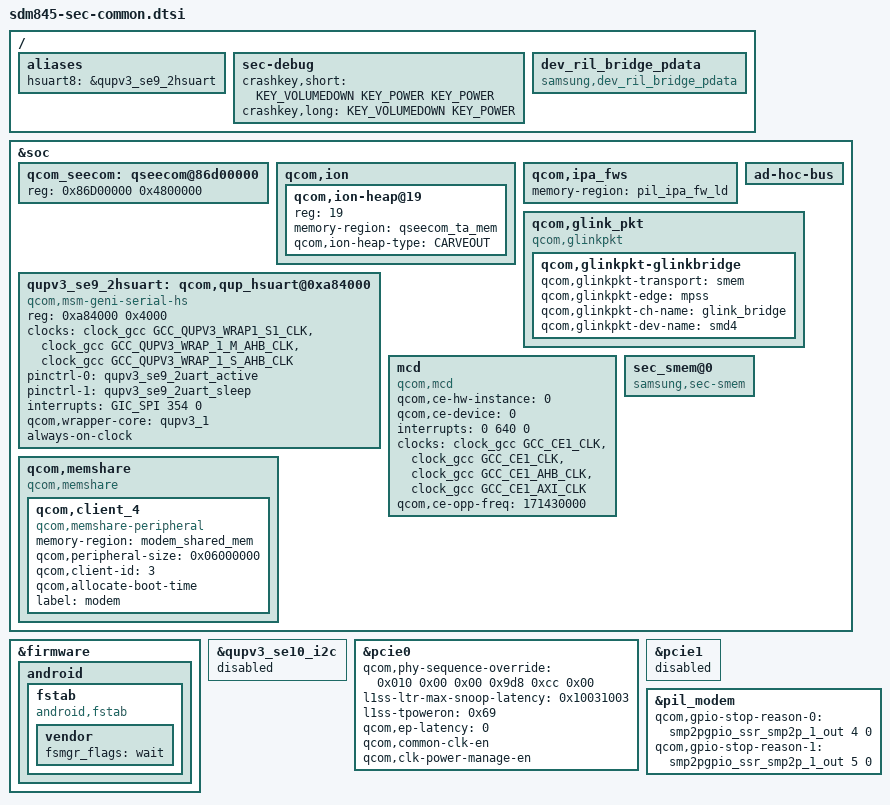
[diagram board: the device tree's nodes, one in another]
/* Copyright (c) 2016-2017, The Linux Foundation. All rights reserved.
 *
 * This program is free software; you can redistribute it and/or modify
 * it under the terms of the GNU General Public License version 2 and
 * only version 2 as published by the Free Software Foundation.
 *
 * This program is distributed in the hope that it will be useful,
 * but WITHOUT ANY WARRANTY; without even the implied warranty of
 * MERCHANTABILITY or FITNESS FOR A PARTICULAR PURPOSE.  See the
 * GNU General Public License for more details.
 */

#include <dt-bindings/input/linux-event-codes.h>
#include "sdm845-sec-memory-common.dtsi"
#include "sdm845-sec-argos-common.dtsi"
#include "input_booster.dtsi"

/{
	aliases {
		hsuart8 = &qupv3_se9_2hsuart;
	};

	sec-debug {
		crashkey,short = <KEY_VOLUMEDOWN KEY_POWER KEY_POWER>;
		crashkey,long = <KEY_VOLUMEDOWN KEY_POWER>;
	};

	dev_ril_bridge_pdata {
		compatible = "samsung,dev_ril_bridge_pdata";
		status = "okay";
	};
};

&soc {
	qcom_seecom: qseecom@86d00000 {
		reg = <0x86D00000 0x4800000>;
	};

	qcom,ion {
		/delete-node/ qcom,ion-heap@19;
		qcom,ion-heap@19 { /* QSEECOM TA HEAP */
			reg = <19>;
			memory-region = <&qseecom_ta_mem>;
			qcom,ion-heap-type = "CARVEOUT";
		};
	};

	qcom,ipa_fws {
		memory-region = <&pil_ipa_fw_ld>;
	};

	ad-hoc-bus {
		/delete-node/ mas-qhm-tic;
		/delete-node/ mas-xm-qdss-dap;
	};
	qupv3_se9_2hsuart: qcom,qup_hsuart@0xa84000 {
		compatible = "qcom,msm-geni-serial-hs", "qcom,msm-geni-uart";
		reg = <0xa84000 0x4000>;
		reg-names = "se_phys";
		clock-names = "se-clk", "m-ahb", "s-ahb";
		clocks = <&clock_gcc GCC_QUPV3_WRAP1_S1_CLK>,
			<&clock_gcc GCC_QUPV3_WRAP_1_M_AHB_CLK>,
			<&clock_gcc GCC_QUPV3_WRAP_1_S_AHB_CLK>;
		pinctrl-names = "default", "sleep";
		pinctrl-0 = <&qupv3_se9_2uart_active>;
		pinctrl-1 = <&qupv3_se9_2uart_sleep>;
		interrupts = <GIC_SPI 354 0>;
		qcom,wrapper-core = <&qupv3_1>;
		status = "ok";
		always-on-clock;
	};

	qcom,glink_pkt {
		compatible = "qcom,glinkpkt";

		qcom,glinkpkt-glinkbridge {
			qcom,glinkpkt-transport = "smem";
			qcom,glinkpkt-edge = "mpss";
			qcom,glinkpkt-ch-name = "glink_bridge";
			qcom,glinkpkt-dev-name = "smd4";
		};
	};

	mcd {
		compatible = "qcom,mcd";
		qcom,ce-hw-instance = <0>;
		qcom,ce-device = <0>;
		interrupts = <0 640 0>;
		interrupt-names = "mcd_irq";
		clock-names = "core_clk_src", "core_clk",
				"iface_clk", "bus_clk";
		clocks = <&clock_gcc GCC_CE1_CLK>,
				<&clock_gcc GCC_CE1_CLK>,
				<&clock_gcc GCC_CE1_AHB_CLK>,
				<&clock_gcc GCC_CE1_AXI_CLK>;
				qcom,ce-opp-freq = <171430000>;
	};

	sec_smem@0 {
		compatible = "samsung,sec-smem";
		status = "okay";
	};

	qcom,memshare {
		compatible = "qcom,memshare";

		qcom,client_4 {
			compatible = "qcom,memshare-peripheral";
			memory-region = <&modem_shared_mem>;
			qcom,peripheral-size = <0x06000000>;
			qcom,client-id = <3>;
			qcom,allocate-boot-time;
			label = "modem";
		};
	};
};

&firmware {
	android {
		fstab {
			compatible = "android,fstab";
			vendor {
				/delete-property/fsmgr_flags;
				fsmgr_flags = "wait";
			};
		};
	};
};


&qupv3_se10_i2c {
	status = "disabled";
	/delete-node/ qcom,smb1355@8;
	/delete-node/ qcom,smb1355@c;
};

&pcie0 {
	/* PCIe phy configuration for SSC(0x010) to enable(0x01), disable(0x00) */
	qcom,phy-sequence-override = <0x010 0x00 0x00
					0x9d8 0xcc 0x00>;

	l1ss-ltr-max-snoop-latency = <0x10031003>;
	l1ss-tpoweron = <0x69>; /* 130us */

	qcom,ep-latency = <0>;

	qcom,common-clk-en;
	qcom,clk-power-manage-en;
};

&pcie1 {
	status = "disabled";
};

&pil_modem {
	/* GPIO output to mss */
	qcom,gpio-stop-reason-0 = <&smp2pgpio_ssr_smp2p_1_out 4 0>;
	qcom,gpio-stop-reason-1 = <&smp2pgpio_ssr_smp2p_1_out 5 0>;
};
